# STM32U5A9 register map
File version: 0.2
CPU: CM33 r0p1, little endian, MPU, FPU, 4 interrupt priority bits
Registers are 32-bit, read-write, reset 0x0 unless marked. A register's access mark holds for its fields unless they carry their own. Offsets are from the block's base; [hi:lo] are bit positions; {n}, {i} and the like mark numbered series; 'fields as' and 'values as' point back to an identical list.

## GTZC1_TZSC
Base 0x40032400
Same registers: SEC_GTZC1_TZSC 0x50032400
0x00 TZSC_CR — TZSC control register
  [0] LCK — lock the configuration of GTZC1_TZSC_SECCFGRx and GTZC1_TZSC_PRIVCFGRx registers until next reset
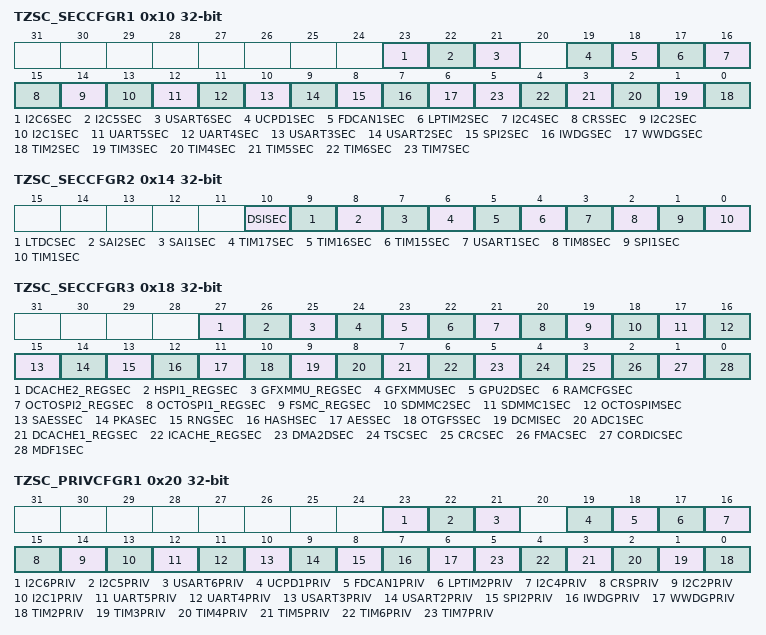
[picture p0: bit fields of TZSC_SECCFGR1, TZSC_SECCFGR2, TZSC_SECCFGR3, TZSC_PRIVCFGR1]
0x10 TZSC_SECCFGR1 — TZSC secure configuration register 1
  [23] I2C6SEC
  [22] I2C5SEC
  [21] USART6SEC
  [19] UCPD1SEC — secure access mode for UCPD1
  [18] FDCAN1SEC — secure access mode for FDCAN1
  [17] LPTIM2SEC — secure access mode for LPTIM2
  [16] I2C4SEC — secure access mode for I2C4
  [15] CRSSEC — secure access mode for CRS
  [14] I2C2SEC — secure access mode for I2C2
  [13] I2C1SEC — secure access mode for I2C1
  [12] UART5SEC — secure access mode for UART5
  [11] UART4SEC — secure access mode for UART4
  [10] USART3SEC — secure access mode for USART3
  [9] USART2SEC — secure access mode for USART2
  [8] SPI2SEC — secure access mode for SPI2
  [7] IWDGSEC — secure access mode for IWDG
  [6] WWDGSEC — secure access mode for WWDG
  [n-2] TIM{n}SEC (n=2..7) — secure access mode for TIM{n}
0x14 TZSC_SECCFGR2 — TZSC secure configuration register 2
  [10] DSISEC
  [9] LTDCSEC
  [8] SAI2SEC — secure access mode for SAI2
  [7] SAI1SEC — secure access mode for SAI1
  [6] TIM17SEC — secure access mode for TIM7
  [5] TIM16SEC — secure access mode for TIM6
  [4] TIM15SEC — secure access mode for TIM5
  [3] USART1SEC — secure access mode for USART1
  [2] TIM8SEC — secure access mode for TIM8
  [1] SPI1SEC — secure access mode for SPI1
  [0] TIM1SEC — secure access mode for TIM1
0x18 TZSC_SECCFGR3 — TZSC secure configuration register 3
  [27] DCACHE2_REGSEC
  [26] HSPI1_REGSEC
  [25] GFXMMU_REGSEC
  [24] GFXMMUSEC
  [23] GPU2DSEC
  [22] RAMCFGSEC — secure access mode for RAMCFG
  [21] OCTOSPI2_REGSEC — secure access mode for OCTOSPI2 registers
  [20] OCTOSPI1_REGSEC — secure access mode for OCTOSPI1 registers
  [19] FSMC_REGSEC — secure access mode for FSMC registers
  [18] SDMMC2SEC — secure access mode for SDMMC1
  [17] SDMMC1SEC — secure access mode for SDMMC2
  [16] OCTOSPIMSEC — secure access mode for OCTOSPIM
  [15] SAESSEC — secure access mode for SAES
  [14] PKASEC — secure access mode for PKA
  [13] RNGSEC — secure access mode for RNG
  [12] HASHSEC — secure access mode for HASH
  [11] AESSEC — secure access mode for AES
  [10] OTGFSSEC — secure access mode for OTG_FS
  [9] DCMISEC — secure access mode for DCMI
  [8] ADC1SEC — secure access mode for ADC1
  [7] DCACHE1_REGSEC — secure access mode for DCACHE1 registers
  [6] ICACHE_REGSEC — secure access mode for ICACHE registers
  [5] DMA2DSEC — secure access mode for register of DMA2D
  [4] TSCSEC — secure access mode for TSC
  [3] CRCSEC — secure access mode for CRC
  [2] FMACSEC — secure access mode for FMAC
  [1] CORDICSEC — secure access mode for CORDIC
  [0] MDF1SEC — secure access mode for MDF1
0x20 TZSC_PRIVCFGR1 — TZSC privilege configuration register 1
  [23] I2C6PRIV
  [22] I2C5PRIV
  [21] USART6PRIV
  [19] UCPD1PRIV — privileged access mode for UCPD1
  [18] FDCAN1PRIV — privileged access mode for FDCAN1
  [17] LPTIM2PRIV — privileged access mode for LPTIM2
  [16] I2C4PRIV — privileged access mode for I2C4
  [15] CRSPRIV — privileged access mode for CRS
  [14] I2C2PRIV — privileged access mode for I2C2
  [13] I2C1PRIV — privileged access mode for I2C1
  [12] UART5PRIV — privileged access mode for UART5
  [11] UART4PRIV — privileged access mode for UART4
  [10] USART3PRIV — privileged access mode for USART3
  [9] USART2PRIV — privileged access mode for USART2
  [8] SPI2PRIV — privileged access mode for SPI2
  [7] IWDGPRIV — privileged access mode for IWDG
  [6] WWDGPRIV — privileged access mode for WWDG
  [n-2] TIM{n}PRIV (n=2..7) — privileged access mode for TIM{n}
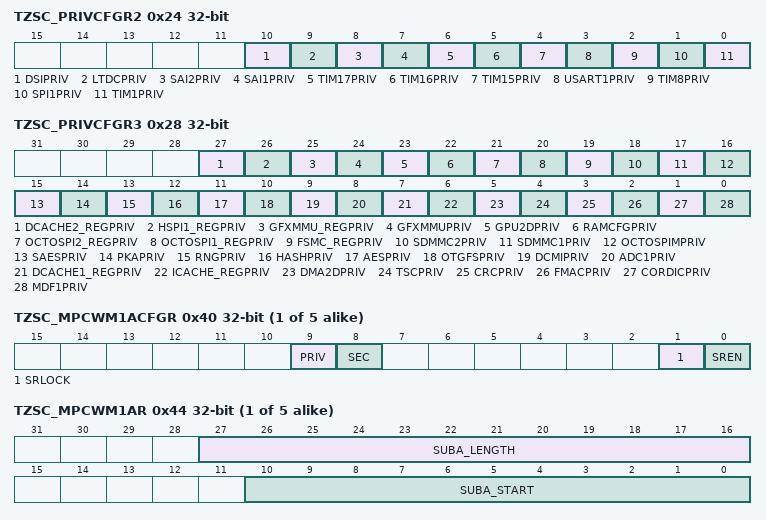
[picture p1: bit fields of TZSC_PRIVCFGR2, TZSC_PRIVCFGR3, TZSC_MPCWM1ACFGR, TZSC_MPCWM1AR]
0x24 TZSC_PRIVCFGR2 — TZSC privilege configuration register 2
  [10] DSIPRIV
  [9] LTDCPRIV
  [8] SAI2PRIV — privileged access mode for SAI2
  [7] SAI1PRIV — privileged access mode for SAI1
  [6] TIM17PRIV — privileged access mode for TIM17
  [5] TIM16PRIV — privileged access mode for TIM16
  [4] TIM15PRIV — privileged access mode for TIM15
  [3] USART1PRIV — privileged access mode for USART1
  [2] TIM8PRIV — privileged access mode for TIM8
  [1] SPI1PRIV — privileged access mode for SPI1PRIV
  [0] TIM1PRIV — privileged access mode for TIM1
0x28 TZSC_PRIVCFGR3 — TZSC privilege configuration register 3
  [27] DCACHE2_REGPRIV
  [26] HSPI1_REGPRIV
  [25] GFXMMU_REGPRIV
  [24] GFXMMUPRIV
  [23] GPU2DPRIV
  [22] RAMCFGPRIV — privileged access mode for RAMCFG
  [21] OCTOSPI2_REGPRIV — privileged access mode for OCTOSPI2
  [20] OCTOSPI1_REGPRIV — privileged access mode for OCTOSPI1
  [19] FSMC_REGPRIV — privileged access mode for FSMC registers
  [18] SDMMC2PRIV — privileged access mode for SDMMC1
  [17] SDMMC1PRIV — privileged access mode for SDMMC2
  [16] OCTOSPIMPRIV — privileged access mode for OCTOSPIM
  [15] SAESPRIV — privileged access mode for SAES
  [14] PKAPRIV — privileged access mode for PKA
  [13] RNGPRIV — privileged access mode for RNG
  [12] HASHPRIV — privileged access mode for HASH
  [11] AESPRIV — privileged access mode for AES
  [10] OTGFSPRIV — privileged access mode for OTG_FS
  [9] DCMIPRIV — privileged access mode for DCMI
  [8] ADC1PRIV — privileged access mode for ADC1
  [7] DCACHE1_REGPRIV — privileged access mode for DCACHE1 registers
  [6] ICACHE_REGPRIV — privileged access mode for ICACHE registers
  [5] DMA2DPRIV — privileged access mode for register of DMA2D
  [4] TSCPRIV — privileged access mode for TSC
  [3] CRCPRIV — privileged access mode for CRC
  [2] FMACPRIV — privileged access mode for FMAC
  [1] CORDICPRIV — privileged access mode for CORDIC
  [0] MDF1PRIV — privileged access mode for MDF1
{0x30+0x10*i} TZSC_MPCWM{i}ACFGR (i=1..5) — TZSC memory {i} sub-region A watermark configuration register
  [9] PRIV — Privileged sub-region
  [8] SEC — Secure sub-region
  [1] SRLOCK — Sub-region lock
  [0] SREN — Sub-region enable
{0x34+0x10*i} TZSC_MPCWM{i}AR (i=1..5) — TZSC memory {i} sub-region A watermark register
  [27:16] SUBA_LENGTH — Length of sub-region A
  [10:0] SUBA_START — Start of sub-region A
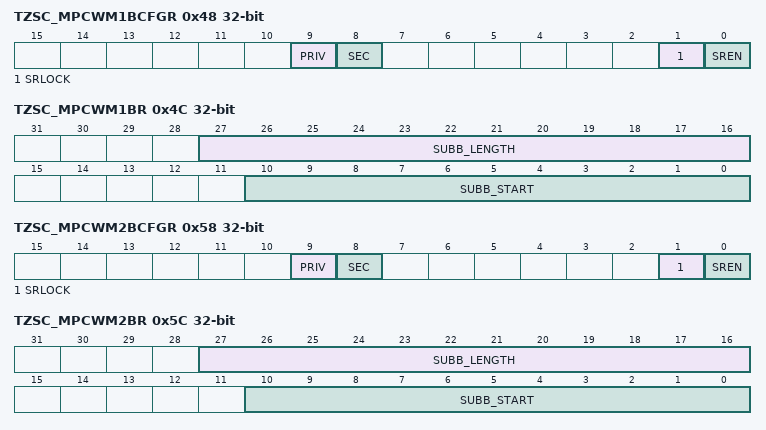
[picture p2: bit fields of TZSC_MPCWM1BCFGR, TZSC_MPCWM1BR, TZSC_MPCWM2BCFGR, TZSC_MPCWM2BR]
0x48 TZSC_MPCWM1BCFGR — TZSC memory 1 sub-region B watermark configuration register
  fields as TZSC_MPCWM1ACFGR
0x4C TZSC_MPCWM1BR — TZSC memory 1 sub-region B watermark register
  [27:16] SUBB_LENGTH — Length of sub-region A
  [10:0] SUBB_START — Start of sub-region A
0x58 TZSC_MPCWM2BCFGR — TZSC memory 2 sub-region B watermark configuration register
  fields as TZSC_MPCWM1ACFGR
0x5C TZSC_MPCWM2BR — TZSC memory 2 sub-region B watermark register
  fields as TZSC_MPCWM1BR
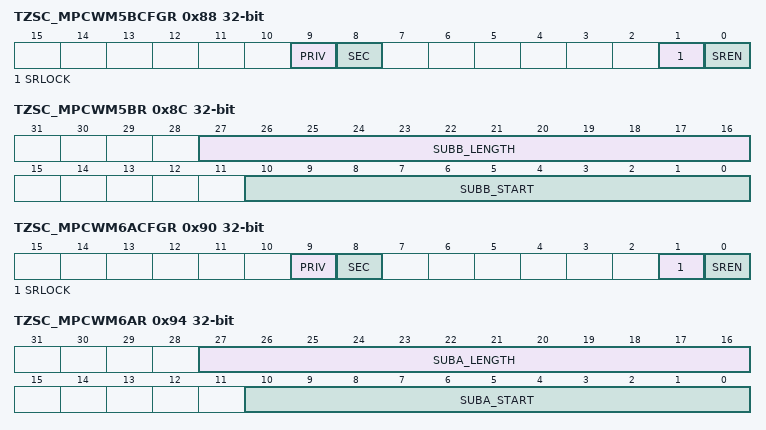
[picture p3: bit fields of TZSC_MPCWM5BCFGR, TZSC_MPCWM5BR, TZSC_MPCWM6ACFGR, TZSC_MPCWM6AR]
0x88 TZSC_MPCWM5BCFGR — TZSC memory 5 sub-region B watermark configuration register
  fields as TZSC_MPCWM1ACFGR
0x8C TZSC_MPCWM5BR — TZSC memory 5 sub-region B watermark register
  fields as TZSC_MPCWM1BR
0x90 TZSC_MPCWM6ACFGR — TZSC memory 6 sub-region B watermark configuration register
  fields as TZSC_MPCWM1ACFGR
0x94 TZSC_MPCWM6AR — TZSC memory 6 sub-region B watermark register
  fields as TZSC_MPCWM1AR
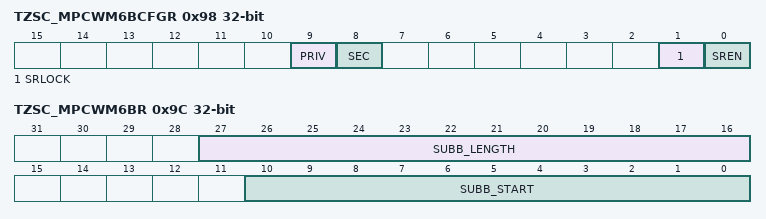
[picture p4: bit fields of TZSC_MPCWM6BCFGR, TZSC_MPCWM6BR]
0x98 TZSC_MPCWM6BCFGR — TZSC memory 6 sub-region B watermark configuration register
  fields as TZSC_MPCWM1ACFGR
0x9C TZSC_MPCWM6BR — TZSC memory 6 sub-region B watermark register
  fields as TZSC_MPCWM1BR
